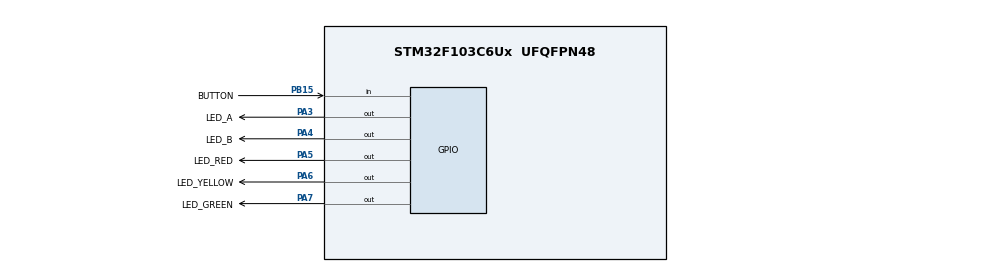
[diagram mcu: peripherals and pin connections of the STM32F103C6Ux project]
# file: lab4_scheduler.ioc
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Mcu.Family=STM32F1
Mcu.Name=STM32F103C6Ux
Mcu.Package=UFQFPN48
NVIC.PriorityGroup=NVIC_PRIORITYGROUP_4
NVIC.TIM3_IRQn=true\:0\:0\:false\:false\:true\:true\:true\:true
PA3.GPIO_Label=LED_A
PA3.Signal=GPIO_Output
PA4.GPIO_Label=LED_B
PA4.Signal=GPIO_Output
PA5.GPIO_Label=LED_RED
PA5.Signal=GPIO_Output
PA6.GPIO_Label=LED_YELLOW
PA6.Signal=GPIO_Output
PA7.GPIO_Label=LED_GREEN
PA7.Signal=GPIO_Output
PB15.GPIO_Label=BUTTON
PB15.GPIO_PuPd=GPIO_PULLUP
PB15.Signal=GPIO_Input
ProjectManager.HeapSize=0x200
ProjectManager.StackSize=0x400
ProjectManager.TargetToolchain=STM32CubeIDE
RCC.APB1Freq_Value=8000000
RCC.APB2Freq_Value=8000000
TIM3.Period=9
TIM3.Prescaler=7999
VP_TIM3_VS_ClockSourceINT.Mode=Internal
board=custom

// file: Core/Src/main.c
/* USER CODE BEGIN Header */
/**
  ******************************************************************************
  * @file           : main.c
  * @brief          : Main program body
  ******************************************************************************
  * @attention
  *
  * Copyright (c) 2022 STMicroelectronics.
  * All rights reserved.
  *
  * This software is licensed under terms that can be found in the LICENSE file
  * in the root directory of this software component.
  * If no LICENSE file comes with this software, it is provided AS-IS.
  *
  ******************************************************************************
  */
/* USER CODE END Header */
#include "main.h"
#include "tim.h"
#include "gpio.h"

/* USER CODE BEGIN Includes */
#include "stim_manip.h"
#include "component.h"
#include "scheduler.h"
/* USER CODE END Includes */

void SystemClock_Config(void);

int main(void)
{

  /* MCU Configuration--------------------------------------------------------*/

  /* Reset of all peripherals, Initializes the Flash interface and the Systick. */
  HAL_Init();

  /* Configure the system clock */
  SystemClock_Config();

  /* USER CODE BEGIN SysInit */
  HAL_TIM_Base_Start_IT(&htim3);
  /* USER CODE END SysInit */

  /* Initialize all configured peripherals */
  MX_GPIO_Init();
  MX_TIM3_Init();
  /* USER CODE BEGIN 2 */

//  Software_Timer_Init();
  /* USER CODE END 2 */

  /* Infinite loop */
  /* USER CODE BEGIN WHILE */
  while (1)
  {
//	  if (standardTime->flag == 1){
//		  standardTime->Set_Default(standardTime);
//		  HAL_GPIO_TogglePin(LED_GREEN_GPIO_Port, LED_GREEN_Pin);
//	  }
    /* USER CODE END WHILE */

  }
}

void SystemClock_Config(void)
{
  RCC_OscInitTypeDef RCC_OscInitStruct = {0};
  RCC_ClkInitTypeDef RCC_ClkInitStruct = {0};

  /** Initializes the RCC Oscillators according to the specified parameters
  * in the RCC_OscInitTypeDef structure.
  */
  RCC_OscInitStruct.OscillatorType = RCC_OSCILLATORTYPE_HSI;
  RCC_OscInitStruct.HSIState = RCC_HSI_ON;
  RCC_OscInitStruct.HSICalibrationValue = RCC_HSICALIBRATION_DEFAULT;
  RCC_OscInitStruct.PLL.PLLState = RCC_PLL_NONE;
  if (HAL_RCC_OscConfig(&RCC_OscInitStruct) != HAL_OK)
  {
    Error_Handler();
  }

  /** Initializes the CPU, AHB and APB buses clocks
  */
  RCC_ClkInitStruct.ClockType = RCC_CLOCKTYPE_HCLK|RCC_CLOCKTYPE_SYSCLK
                              |RCC_CLOCKTYPE_PCLK1|RCC_CLOCKTYPE_PCLK2;
  RCC_ClkInitStruct.SYSCLKSource = RCC_SYSCLKSOURCE_HSI;
  RCC_ClkInitStruct.AHBCLKDivider = RCC_SYSCLK_DIV1;
  RCC_ClkInitStruct.APB1CLKDivider = RCC_HCLK_DIV1;
  RCC_ClkInitStruct.APB2CLKDivider = RCC_HCLK_DIV1;

  if (HAL_RCC_ClockConfig(&RCC_ClkInitStruct, FLASH_LATENCY_0) != HAL_OK)
  {
    Error_Handler();
  }
}

/* USER CODE BEGIN 4 */
int counter = 100;
void HAL_TIM_PeriodElapsedCallback(TIM_HandleTypeDef *htim){
	if (htim->Instance == TIM3){
		if (counter > 0){
			counter--;
			if (counter <= 0){
				counter = 10;
				HAL_GPIO_TogglePin(LED_GREEN_GPIO_Port, LED_GREEN_Pin);
			}
		}
	}
}
/* USER CODE END 4 */

void Error_Handler(void)
{
  __disable_irq();
  while (1)
  {
  }
}
